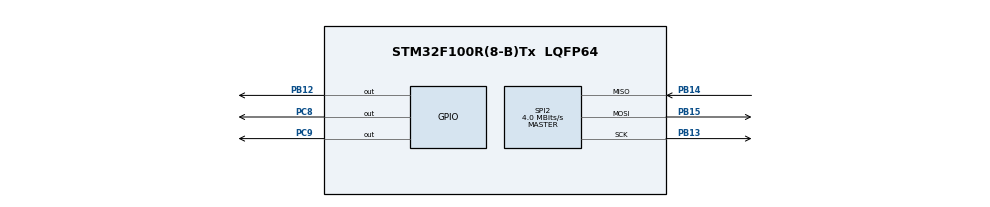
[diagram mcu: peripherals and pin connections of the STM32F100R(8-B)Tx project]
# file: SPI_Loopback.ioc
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Mcu.Family=STM32F1
Mcu.Name=STM32F100R(8-B)Tx
Mcu.Package=LQFP64
NVIC.PriorityGroup=NVIC_PRIORITYGROUP_4
PA13.Mode=Serial_Wire
PA13.Signal=SYS_JTMS-SWDIO
PA14.Mode=Serial_Wire
PA14.Signal=SYS_JTCK-SWCLK
PB12.Signal=GPIO_Output
PB13.Mode=Full_Duplex_Master
PB13.Signal=SPI2_SCK
PB14.Mode=Full_Duplex_Master
PB14.Signal=SPI2_MISO
PB15.Mode=Full_Duplex_Master
PB15.Signal=SPI2_MOSI
PC8.Signal=GPIO_Output
PC9.Signal=GPIO_Output
ProjectManager.HeapSize=0x200
ProjectManager.StackSize=0x400
ProjectManager.TargetToolchain=Makefile
RCC.APB1Freq_Value=8000000
RCC.APB2Freq_Value=8000000
SPI2.CalculateBaudRate=4.0 MBits/s
SPI2.Direction=SPI_DIRECTION_2LINES
SPI2.Mode=SPI_MODE_MASTER
SPI2.VirtualType=VM_MASTER
board=custom

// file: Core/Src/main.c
/* USER CODE BEGIN Header */
/**
 ******************************************************************************
 * @file           : main.c
 * @brief          : Main program body
 ******************************************************************************
 * @attention
 *
 * Copyright (c) 2025 STMicroelectronics.
 * All rights reserved.
 *
 * This software is licensed under terms that can be found in the LICENSE file
 * in the root directory of this software component.
 * If no LICENSE file comes with this software, it is provided AS-IS.
 *
 ******************************************************************************
 */
/* USER CODE END Header */
#include "main.h"

/* USER CODE BEGIN PD */
#define EEPROM_INSTR_READ 0x03  // read data
#define EEPROM_INSTR_WRITE 0x02 // write data
#define EEPROM_INSTR_WRDI 0x04  // set the write disable
#define EEPROM_INSTR_WREN 0x06  // set the write enable
#define EEPROM_INSTR_RDSR 0x05  // read status register
#define EEPROM_INSTR_WRSR 0x01  // write status register

#define EEPROM_CS_LOW()                                                        \
  HAL_GPIO_WritePin(GPIOB, GPIO_PIN_12, GPIO_PIN_RESET) // Select slave Pin
#define EEPROM_CS_HIGH()                                                       \
  HAL_GPIO_WritePin(GPIOB, GPIO_PIN_12, GPIO_PIN_SET) // Select slave Pin
/* USER CODE END PD */

SPI_HandleTypeDef hspi2;

void SystemClock_Config(void);
static void MX_GPIO_Init(void);
static void MX_SPI2_Init(void);

/* USER CODE BEGIN 0 */
uint8_t EEPROM_ReadByte(uint16_t addr) {
  uint8_t data;
  uint8_t msg[3];
  msg[0] = EEPROM_INSTR_READ;
  msg[1] = (addr >> 8) & 0xFF; // MSB wird um 8 bits nach rechts verschoben
                               // und anschlißen wird der rest "abgeschnitten"
  msg[2] = addr & 0xFF;

  EEPROM_CS_LOW();
  HAL_SPI_Transmit(&hspi2, msg, 3,
                   HAL_MAX_DELAY); // separates transmit und receive, da hier
                                   // ers die adresse gesendet werden musss
                                   // bevor diese ausgelesen werden kann
  HAL_SPI_Receive(&hspi2, &data, 1, HAL_MAX_DELAY);
  HAL_Delay(100);

  EEPROM_CS_HIGH();

  return data;
}

// eleganterere Lösung anstelle den Zeitraum des schreibens durch beliebige zeit
// zu warten (zu lang, zu kuurz ....)
uint8_t EEPROM_ReadStatus(void) {
  uint8_t instruction = EEPROM_INSTR_RDSR;
  uint8_t status;

  EEPROM_CS_LOW();
  HAL_SPI_Transmit(&hspi2, &instruction, 1, HAL_MAX_DELAY);
  HAL_SPI_Receive(&hspi2, &status, 1, HAL_MAX_DELAY);
  EEPROM_CS_HIGH();

  return status;
}
void EEPROM_WriteByte(uint16_t addr, uint8_t counter) {
  uint8_t wren = EEPROM_INSTR_WREN;
  EEPROM_CS_LOW();
  HAL_SPI_Transmit(&hspi2, &wren, 1, HAL_MAX_DELAY);
  EEPROM_CS_HIGH();

  HAL_Delay(10);

  uint8_t data = 0x00 + counter;
  uint8_t msg[4];

  msg[0] = EEPROM_INSTR_WRITE;
  msg[1] = (addr >> 8) & 0xFF;
  msg[2] = addr & 0xFF;
  msg[3] = data;

  EEPROM_CS_LOW();
  HAL_SPI_Transmit(&hspi2, msg, 4, HAL_MAX_DELAY);
  EEPROM_CS_HIGH();

  // Self-Timed Erase and Write Cycles(5 ms maximum) --> datasheet
  while (EEPROM_ReadStatus() & 0x01) // uns interessiert nur erstes bit
  {
    // Write-In-Process (WIP) ist anschienend gesetzt
    // warten bis nächster Prüfung
    HAL_Delay(1);
  }
}
/* USER CODE END 0 */

int main(void) {

  /* MCU Configuration--------------------------------------------------------*/

  /* Reset of all peripherals, Initializes the Flash interface and the Systick.
   */
  HAL_Init();

  /* Configure the system clock */
  SystemClock_Config();

  /* Initialize all configured peripherals */
  MX_GPIO_Init();
  MX_SPI2_Init();

  /* Infinite loop */
  /* USER CODE BEGIN WHILE */
  GPIO_PinState buttonStatus;
  GPIO_PinState last_button_state = GPIO_PIN_RESET;
  uint8_t counter = 0;
  // const uint8_t message[] = "hello!1";
  // uint8_t empfangen[sizeof(message)];
  while (1) {
    HAL_GPIO_WritePin(GPIOC, GPIO_PIN_8, GPIO_PIN_RESET);
    HAL_GPIO_WritePin(GPIOC, GPIO_PIN_9, GPIO_PIN_RESET);

    buttonStatus = HAL_GPIO_ReadPin(GPIOA, GPIO_PIN_0);

    if (buttonStatus == GPIO_PIN_SET && last_button_state == GPIO_PIN_RESET) {
      HAL_GPIO_TogglePin(GPIOC, GPIO_PIN_8);
      HAL_GPIO_TogglePin(GPIOC, GPIO_PIN_9);
      EEPROM_WriteByte(0x0000, counter);
      volatile uint8_t value = EEPROM_ReadByte(0x0000);
      counter++;
    }
    last_button_state = buttonStatus;

    HAL_Delay(50); // debouncen -> alternativ software zietfenster mit counter
                   // beipsilsweise

    // HAL_GPIO_WritePin(GPIOC, GPIO_PIN_8, GPIO_PIN_RESET);
    // HAL_GPIO_WritePin(GPIOC, GPIO_PIN_9, GPIO_PIN_RESET);
    // HAL_Delay(1000);
    /* USER CODE END WHILE */

    /* USER CODE BEGIN 3 */
    //   HAL_GPIO_WritePin(GPIOC, GPIO_PIN_8, GPIO_PIN_SET);

    //   HAL_Delay(1000);

    //   HAL_SPI_TransmitReceive(&hspi2, message, empfangen, (uint16_t)8,
    //   HAL_MAX_DELAY); // Gesendete Bytes kommen direkt zurück, sofort
    //   nutzbar, da master und slave dieselben sind (loopback)

    //   if (strcmp(message, empfangen) == 0) {
    //     HAL_GPIO_WritePin(GPIOC, GPIO_PIN_8, GPIO_PIN_SET);
    //     HAL_GPIO_WritePin(GPIOC, GPIO_PIN_9, GPIO_PIN_SET);
    //   }

    //   HAL_Delay(3000);
  }
  /* USER CODE END 3 */
}

void SystemClock_Config(void) {
  RCC_OscInitTypeDef RCC_OscInitStruct = {0};
  RCC_ClkInitTypeDef RCC_ClkInitStruct = {0};

  /** Initializes the RCC Oscillators according to the specified parameters
   * in the RCC_OscInitTypeDef structure.
   */
  RCC_OscInitStruct.OscillatorType = RCC_OSCILLATORTYPE_HSI;
  RCC_OscInitStruct.HSIState = RCC_HSI_ON;
  RCC_OscInitStruct.HSICalibrationValue = RCC_HSICALIBRATION_DEFAULT;
  RCC_OscInitStruct.PLL.PLLState = RCC_PLL_NONE;
  if (HAL_RCC_OscConfig(&RCC_OscInitStruct) != HAL_OK) {
    Error_Handler();
  }

  /** Initializes the CPU, AHB and APB buses clocks
   */
  RCC_ClkInitStruct.ClockType = RCC_CLOCKTYPE_HCLK | RCC_CLOCKTYPE_SYSCLK |
                                RCC_CLOCKTYPE_PCLK1 | RCC_CLOCKTYPE_PCLK2;
  RCC_ClkInitStruct.SYSCLKSource = RCC_SYSCLKSOURCE_HSI;
  RCC_ClkInitStruct.AHBCLKDivider = RCC_SYSCLK_DIV1;
  RCC_ClkInitStruct.APB1CLKDivider = RCC_HCLK_DIV1;
  RCC_ClkInitStruct.APB2CLKDivider = RCC_HCLK_DIV1;

  if (HAL_RCC_ClockConfig(&RCC_ClkInitStruct, FLASH_LATENCY_0) != HAL_OK) {
    Error_Handler();
  }
}

static void MX_SPI2_Init(void) {

  /* SPI2 parameter configuration*/
  hspi2.Instance = SPI2;
  hspi2.Init.Mode = SPI_MODE_MASTER;
  hspi2.Init.Direction = SPI_DIRECTION_2LINES;
  hspi2.Init.DataSize = SPI_DATASIZE_8BIT;
  hspi2.Init.CLKPolarity = SPI_POLARITY_LOW;
  hspi2.Init.CLKPhase = SPI_PHASE_1EDGE;
  hspi2.Init.NSS = SPI_NSS_SOFT;
  hspi2.Init.BaudRatePrescaler = SPI_BAUDRATEPRESCALER_2;
  hspi2.Init.FirstBit = SPI_FIRSTBIT_MSB;
  hspi2.Init.TIMode = SPI_TIMODE_DISABLE;
  hspi2.Init.CRCCalculation = SPI_CRCCALCULATION_DISABLE;
  hspi2.Init.CRCPolynomial = 10;
  if (HAL_SPI_Init(&hspi2) != HAL_OK) {
    Error_Handler();
  }
}

static void MX_GPIO_Init(void) {
  GPIO_InitTypeDef GPIO_InitStruct = {0};

  /* GPIO Ports Clock Enable */
  __HAL_RCC_GPIOB_CLK_ENABLE();
  __HAL_RCC_GPIOC_CLK_ENABLE();
  __HAL_RCC_GPIOA_CLK_ENABLE();

  /*Configure GPIO pin Output Level */
  HAL_GPIO_WritePin(GPIOB, GPIO_PIN_12, GPIO_PIN_RESET);

  /*Configure GPIO pin Output Level */
  HAL_GPIO_WritePin(GPIOC, GPIO_PIN_8 | GPIO_PIN_9, GPIO_PIN_RESET);

  /*Configure GPIO pin : PB12 */
  GPIO_InitStruct.Pin = GPIO_PIN_12;
  GPIO_InitStruct.Mode = GPIO_MODE_OUTPUT_PP;
  GPIO_InitStruct.Pull = GPIO_NOPULL;
  GPIO_InitStruct.Speed = GPIO_SPEED_FREQ_LOW;
  HAL_GPIO_Init(GPIOB, &GPIO_InitStruct);

  /*Configure GPIO pins : PC8 PC9 */
  GPIO_InitStruct.Pin = GPIO_PIN_8 | GPIO_PIN_9;
  GPIO_InitStruct.Mode = GPIO_MODE_OUTPUT_PP;
  GPIO_InitStruct.Pull = GPIO_NOPULL;
  GPIO_InitStruct.Speed = GPIO_SPEED_FREQ_LOW;
  HAL_GPIO_Init(GPIOC, &GPIO_InitStruct);

  /*Configure GPIO pin : PA0 */
  GPIO_InitStruct.Pin = GPIO_PIN_0;
  GPIO_InitStruct.Mode = GPIO_MODE_INPUT;
  GPIO_InitStruct.Pull = GPIO_NOPULL;
  HAL_GPIO_Init(GPIOA, &GPIO_InitStruct);

}

void Error_Handler(void) {
  /* USER CODE BEGIN Error_Handler_Debug */
  /* User can add his own implementation to report the HAL error return state
   */
  __disable_irq();
  while (1) {
  }
  /* USER CODE END Error_Handler_Debug */
}

#ifdef USE_FULL_ASSERT
/**
 * @brief  Reports the name of the source file and the source line number
 *         where the assert_param error has occurred.
 * @param  file: pointer to the source file name
 * @param  line: assert_param error line source number
 * @retval None
 */
void assert_failed(uint8_t *file, uint32_t line) {
  /* USER CODE BEGIN 6 */
  /* User can add his own implementation to report the file name and line
     number, ex: printf("Wrong parameters value: file %s on line %d\r\n",
     file, line) */
  /* USER CODE END 6 */
}
#endif /* USE_FULL_ASSERT */
